VERSION ""

NS_ :

BS_:

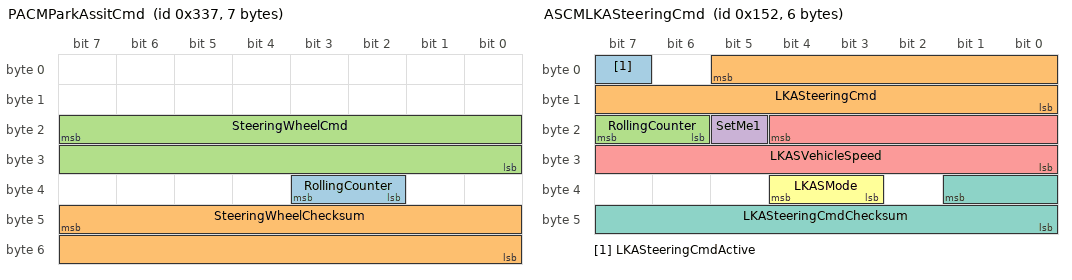
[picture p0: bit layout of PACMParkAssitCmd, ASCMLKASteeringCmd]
BO_ 823 PACMParkAssitCmd: 7 NEO
 SG_ RollingCounter : 35|2@0+ (1,0) [0|0] ""  NEO
 SG_ SteeringWheelChecksum : 47|16@0+ (1,0) [0|0] ""  NEO
 SG_ SteeringWheelCmd : 23|16@0+ (1,0) [0|0] ""  NEO

BO_ 560 EBCMRegen: 6 K17_EBCM
 SG_ Regen : 1|10@0+ (1,0) [0|0] ""  NEO

BO_ 338 ASCMLKASteeringCmd: 6 NEO
 SG_ LKASteeringCmdActive : 7|1@0+ (1,0) [0|0] ""  NEO
 SG_ LKASteeringCmd : 5|14@0- (1,0) [0|0] ""  NEO
 SG_ RollingCounter : 23|2@0+ (1,0) [0|0] ""  NEO
 SG_ SetMe1 : 21|1@0+ (1,0) [0|0] ""  NEO
 SG_ LKASVehicleSpeed : 20|13@0+ (0.22,0) [0|0] "kph" NEO
 SG_ LKASMode : 36|2@0+ (1,0) [0|0] ""  NEO
 SG_ LKASteeringCmdChecksum : 33|10@0+ (1,0) [0|0] ""  NEO

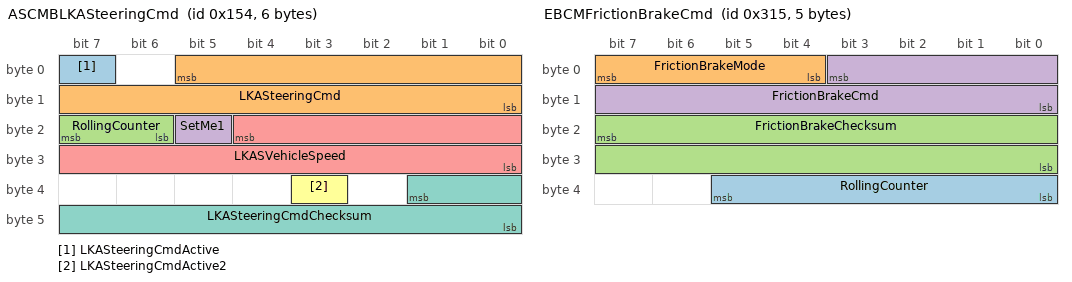
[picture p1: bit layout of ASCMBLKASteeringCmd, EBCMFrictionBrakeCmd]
BO_ 340 ASCMBLKASteeringCmd: 6 NEO
 SG_ LKASteeringCmdActive : 7|1@0+ (1,0) [0|0] ""  NEO
 SG_ LKASteeringCmd : 5|14@0- (1,0) [0|0] ""  NEO
 SG_ RollingCounter : 23|2@0+ (1,0) [0|0] ""  NEO
 SG_ SetMe1 : 21|1@0+ (1,0) [0|0] ""  NEO
 SG_ LKASVehicleSpeed : 20|13@0+ (0.22,0) [0|0] "kph" NEO
 SG_ LKASteeringCmdActive2 : 35|1@0+ (1,0) [0|0] ""  NEO
 SG_ LKASteeringCmdChecksum : 33|10@0+ (1,0) [0|0] ""  NEO

BO_ 368 EBCMFrictionBrakeStatus: 8 K17_EBCM
 SG_ FrictionBrakePressure : 23|16@0+ (1,0) [0|0] ""  NEO

BO_ 789 EBCMFrictionBrakeCmd: 5 K17_EBCM
 SG_ RollingCounter : 37|6@0+ (1,0) [0|0] ""  NEO
 SG_ FrictionBrakeMode : 7|4@0+ (1,0) [0|0] ""  NEO
 SG_ FrictionBrakeChecksum : 23|16@0+ (1,0) [0|0] ""  NEO
 SG_ FrictionBrakeCmd : 3|12@0- (1,0) [0|0] ""  NEO

BO_TX_BU_ 823 : K43_PSCM,NEO;
BO_TX_BU_ 789 : NEO,K17_EBCM;

VAL_ 552 GEAR 1 "P" 2 "R" 3 "N" 4 "D" ;
VAL_ 540 RADAR_HAS_LEAD 0 "NO LEAD" 1 "HAS LEAD" ;
VAL_ 540 RADAR_LEAD_RELATIVE_DISTANCE 0 "NO LEAD" 1 "FARTHEST" 2 "4" 3 "3" 4 "2" 5 "NEAREST" ;
VAL_ 1143 LEFT_BS_STATUS 0 "No object detected" 1 "Object detected in left blindspot" 2 "Object detected in left blindspot with blinker - warning"
